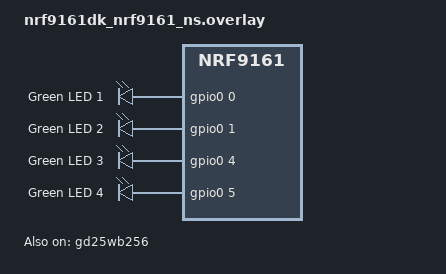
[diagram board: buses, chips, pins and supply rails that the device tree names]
/*
 * Copyright (c) 2023 Nordic Semiconductor ASA
 *
 * SPDX-License-Identifier: LicenseRef-Nordic-5-Clause
 */

/	{
	/delete-node/ leds;

	leds0 {
		compatible = "gpio-leds";
		status = "okay";
		label = "LED0";
		led0: led_0 {
			status = "okay";
			gpios = <&gpio0 0 0>;
			label = "Green LED 1";
		};
	};

	leds1 {
		compatible = "gpio-leds";
		status = "okay";
		label = "LED1";
		led1: led_1 {
			gpios = <&gpio0 1 0>;
			label = "Green LED 2";
		};
	};

	leds2 {
		compatible = "gpio-leds";
		status = "okay";
		label = "LED2";
		led2: led_2 {
			gpios = <&gpio0 4 0>;
			label = "Green LED 3";
		};
	};

	leds3 {
		compatible = "gpio-leds";
		status = "okay";
		label = "LED3";
		led3: led_3 {
			gpios = <&gpio0 5 0>;
			label = "Green LED 4";
		};
	};

	/* Configure partition manager to use gd25wb256 as the external flash */
	chosen {
		nordic,pm-ext-flash = &gd25wb256;
	};

	aliases {
		ext-flash = &gd25wb256;
	};
};

&gd25wb256 {
	status = "okay";
};
